# USB0_VBP2APB_WRAP_CONTROLLER_VBP_CORE_ADDR_MAP register map
Vendor: Texas Instruments
Registers are 32-bit, access per field, reset 0x0 unless marked. A register's access mark holds for its fields unless they carry their own. Offsets are as the file gives them; [hi:lo] are bit positions.

## USB0_VBP2APB_WRAP_CONTROLLER_VBP_CORE_ADDR_MAP (part 7 of 9)
0x181E8 VBP2APB_WRAP__CONTROLLER_VBP__CORE_ADDR_MAP_XECP_HOST_CTRL_LTM_REG2 reset 0x400 — HOST_CTRL_LTM_REG2. This is a vendor defined capability. This register is reserved. This register should not be accessed by software. It is described only for informative purposes.
  [11:0] DEFAULT_PCIE_LTM rw — DEFAULT_PCIE_LTM converted from ns with convert_ns2belt
0x18200 VBP2APB_WRAP__CONTROLLER_VBP__CORE_ADDR_MAP_XECP_AUX_SCRATCHPAD_0 rw — For internal use. This register may be read from or written to at any time, including whilst the CNR field in the USBSTS register is high. This is a vendor defined capability. This register is reserved. This register should not be accessed by software. It is described only for informative purposes.
0x18204 VBP2APB_WRAP__CONTROLLER_VBP__CORE_ADDR_MAP_XECP_AUX_SCRATCHPAD_1 rw — For internal use. This register may be read from or written to at any time, including whilst the CNR field in the USBSTS register is high. This is a vendor defined capability. This register is reserved. This register should not be accessed by software. It is described only for informative purposes.
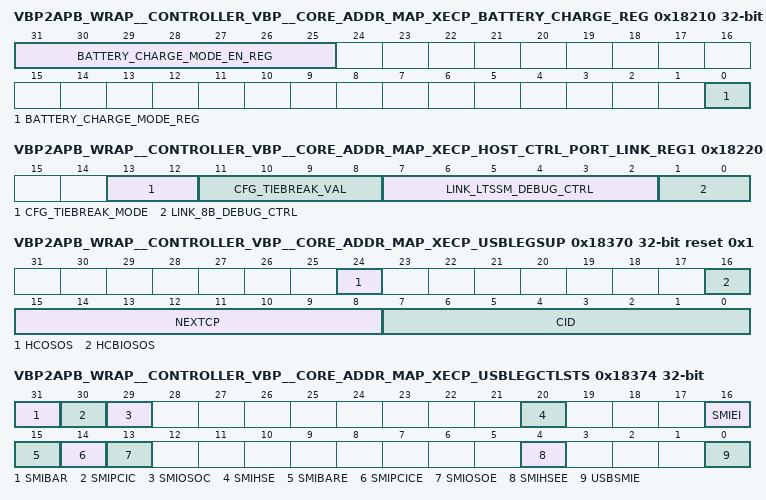
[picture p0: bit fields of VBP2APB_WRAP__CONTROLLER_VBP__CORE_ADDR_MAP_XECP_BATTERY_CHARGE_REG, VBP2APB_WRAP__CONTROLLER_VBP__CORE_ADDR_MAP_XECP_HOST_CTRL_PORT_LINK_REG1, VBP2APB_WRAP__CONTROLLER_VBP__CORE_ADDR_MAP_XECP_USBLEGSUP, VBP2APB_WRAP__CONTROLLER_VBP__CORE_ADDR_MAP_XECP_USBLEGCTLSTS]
0x18210 VBP2APB_WRAP__CONTROLLER_VBP__CORE_ADDR_MAP_XECP_BATTERY_CHARGE_REG access not given — Battery charge mode and enable register. This register may be read from or written to at any time, including whilst the CNR field in the USBSTS register is high. This is a vendor defined capability. This register is reserved. This register should not be accessed by software. It is described only for informative purposes.
  [31:25] BATTERY_CHARGE_MODE_EN_REG rw — The register allows enabling battery charge mode for each USB2 port.
  [0] BATTERY_CHARGE_MODE_REG rw — The register allows setting battery charge mode for each USB2 port.
0x18214 VBP2APB_WRAP__CONTROLLER_VBP__CORE_ADDR_MAP_XECP_BATTERY_CHARGE_REG1 reset 0x13641F4 — Battery charge control register 1. This register may be read from or written to at any time, including whilst the CNR field in the USBSTS register is high. This is a vendor defined capability. This register is reserved. This register should not be accessed by software. It is described only for informative purposes.
  [30:0] BATTERY_CHARGE_CTRL_REG1_DEFAULT rw
0x18218 VBP2APB_WRAP__CONTROLLER_VBP__CORE_ADDR_MAP_XECP_BATTERY_CHARGE_REG2 reset 0x1F4014 — Battery charge control register 2. This register may be read from or written to at any time, including whilst the CNR field in the USBSTS register is high. This is a vendor defined capability. This register is reserved. This register should not be accessed by software. It is described only for informative purposes.
  [23:0] BATTERY_CHARGE_CTRL_REG2_DEFAULT rw
0x1821C VBP2APB_WRAP__CONTROLLER_VBP__CORE_ADDR_MAP_XECP_BATTERY_CHARGE_REG3 ro — Battery charge debug register. This register may be read from or written to at any time, including whilst the CNR field in the USBSTS register is high. This is a vendor defined capability. This register is reserved. This register should not be accessed by software. It is described only for informative purposes.
  [23:0] BATTERY_CHARGE_DEBUG
0x18220 VBP2APB_WRAP__CONTROLLER_VBP__CORE_ADDR_MAP_XECP_HOST_CTRL_PORT_LINK_REG1 rw — Feature #581. This is a vendor defined capability. This register is reserved. This register should not be accessed by software. It is described only for informative purposes.
  [13:12] CFG_TIEBREAK_MODE
  [11:8] CFG_TIEBREAK_VAL
  [7:2] LINK_LTSSM_DEBUG_CTRL — link_debug_ctrl register:.link_ltssm_debug_ctrl. Possible values: stay_in_idle : bit 0 set. stay_in_ts1 : bit 1 set. stay_in_ts2 : bit 2 set. stay_in_tseq : bit 3 set. stay_in_lfps : bit 4 set. timeout_jumpover_en : bit 5 set.
  [1:0] LINK_8B_DEBUG_CTRL — link_debug_ctrl register:.link_8b_debug_ctrl. bit[0]: xmt_d102, bit[1]: xmt_comma.
0x18370 VBP2APB_WRAP__CONTROLLER_VBP__CORE_ADDR_MAP_XECP_USBLEGSUP reset 0x1 — USB Legacy Support Capability. This register is an xHCI extended capability register. This register is used by pre-OS software (BIOS) and the operating system to coordinate ownership of the xHC. This extended capability requires one additional 32-bit register for control/status information (USBLEGCTLSTS). This register is in the Aux Power well. This register may be read from or written to at any time, including whilst the CNR field in the USBSTS register is high.
  [24] HCOSOS rw — HC OS Owned Semaphore, RW. Default = '0'. System software sets this bit to request ownership of the xHC. Ownership is obtained when this bit reads as '1' and the HC BIOS Owned Semaphore bit [HCBIOSOS] reads as '0'.
  [16] HCBIOSOS rw — HC BIOS Owned Semaphore [HCBIOSOS], RW. Default = '0'. The BIOS sets this bit to establish ownership of the xHC. System BIOS will set this bit to '0' in response to a request for ownership of the xHC by system software.
  [15:8] NEXTCP ro — Next Capability Pointer, RO. This field indicates the location of the next capability with respect to the effective address of this capability. A non-zero value in this register indicates a relative offset, in Dwords, from this Dword to the beginning of the next extended capability.
  [7:0] CID ro — USB Legacy Support Capability ID, RO. This capability provides the xHCI Pre-OS to OS Handoff Synchronization support capability.
0x18374 VBP2APB_WRAP__CONTROLLER_VBP__CORE_ADDR_MAP_XECP_USBLEGCTLSTS access not given — USB Legacy Support Control Status. Pre-OS (BIOS) software uses this register to enable System Management Interrupts (SMIs) for every xHCI/USB event it needs to track. Some bits of this register are simply shadow bit of USBSTS register. This register is in the Aux Power well. This register may be read from or written to at any time, including whilst the CNR field in the USBSTS register is high.
  [31] SMIBAR — SMI on BAR, RW1C. Default = '0'. This bit is set to '1' whenever the Base Address Register [BAR] is written. (access R/W1TC)
  [30] SMIPCIC — SMI on PCI Command, RW1C. Default = '0'. This bit is set to '1' whenever the PCI Command Register is written. (access R/W1TC)
  [29] SMIOSOC — SMI on OS Ownership Change, RW1C. Default = '0'. This bit is set to '1' whenever the HC OS Owned Semaphore bit in the USBLEGSUP register transitions from '1' to a '0' or '0' to a '1'. (access R/W1TC)
  [20] SMIHSE ro — SMI on Host System Error, RO. Default = '0'. Shadow bit of Host System Error [HSE] bit in the USBSTS register. Refer to Section 5.4.2 of xHCI specification for definition and effects of the events associated with this bit being set to '1'. To clear this bit to a '0', system software shall write a '1' to the Host System Error [HSE] bit in the USBSTS register.
  [16] SMIEI ro — SMI on Event Interrupt, RO. Default = '0'. Shadow bit of Event Interrupt [EINT] bit in the USBSTS register. Refer to Section 5.4.2 of xHCI specification for definition. This bit follows the state the Event Interrupt [EINT] bit in the USBSTS register, e.g. it automatically clears when EINT clears or set when EINT is set.
  [15] SMIBARE rw — SMI on BAR Enable, RW. Default = '0'. When this bit is '1' and SMI on BAR is '1', then the host controller will issue an SMI.
  [14] SMIPCICE rw — SMI on PCI Command Enable, RW. Default = '0'. When this bit is '1' and SMI on PCI Command is '1', then the host controller will issue an SMI.
  [13] SMIOSOE rw — SMI on OS Ownership Enable, RW. Default = '0'. When this bit is a '1' AND the OS Ownership Change bit is '1', the host controller will issue an SMI.
  [4] SMIHSEE rw — SMI on Host System Error Enable, RW. Default = '0'. When this bit is a '1', and the SMI on Host System Error bit [below] in this register is a '1', the host controller will issue an SMI immediately.
  [0] USBSMIE rw — USB SMI Enable, RW. Default = '0'. When this bit is a '1', and the SMI on Event Interrupt bit [below] in this register is a '1', the host controller will issue an SMI immediately.
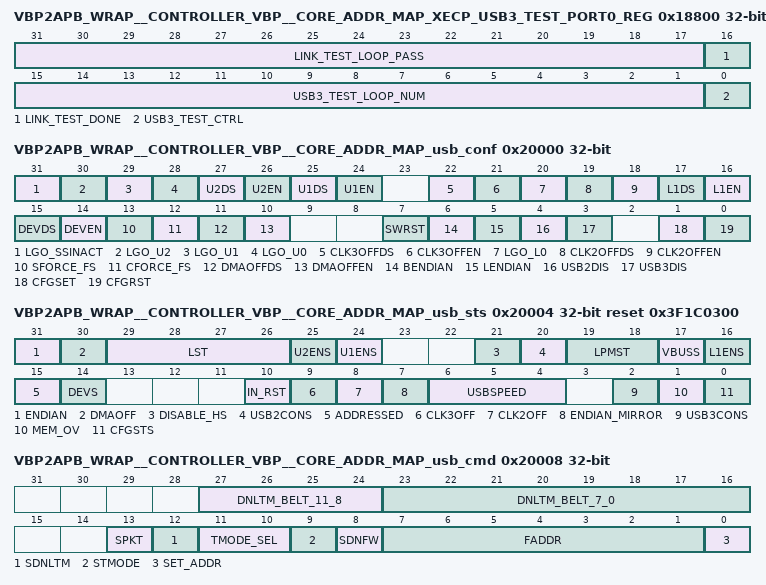
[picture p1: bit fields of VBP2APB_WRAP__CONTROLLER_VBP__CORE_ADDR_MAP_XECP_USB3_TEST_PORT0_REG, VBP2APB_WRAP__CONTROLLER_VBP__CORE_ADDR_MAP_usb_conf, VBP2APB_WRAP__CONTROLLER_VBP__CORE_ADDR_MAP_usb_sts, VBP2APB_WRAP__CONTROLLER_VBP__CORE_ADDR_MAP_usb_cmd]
0x18800 VBP2APB_WRAP__CONTROLLER_VBP__CORE_ADDR_MAP_XECP_USB3_TEST_PORT0_REG — USB3_TEST_PORT_REG. This is a vendor defined capability. This register is reserved. This register should not be accessed by software. It is described only for informative purposes.
  [31:17] LINK_TEST_LOOP_PASS ro
  [16] LINK_TEST_DONE ro — link_test_done This field should not be modified by software
  [15:1] USB3_TEST_LOOP_NUM rw
  [0] USB3_TEST_CTRL rw
0x20000 VBP2APB_WRAP__CONTROLLER_VBP__CORE_ADDR_MAP_usb_conf — Global Configuration Register
  [31] LGO_SSINACT rw — SS.Inactive state entry request [SS mode only]. This bit can be used only if USBSS-DEV is part of the CDNS USB OTG Controller [USB_CAP.OTG_READY bit is 1 while reading]. In other cases should not be used and returns 0 when read. Writing '1' will trigger an attempt to perform transition to SS.Inactive state. Should be used only if Link is in U0 or Recovery state. This bit will be automatically cleared to '0' after link layer finishes SS.Inactive request. Result of the request [link layer enters SS.Inactive or not] can be verified by reading LTS [link state] field in USB_STS register. Writing '0' has no effect
  [30] LGO_U2 rw — U2 state entry request [SS mode only]. Writing '1' will trigger an attempt to perform transition to U2 state. This bit will be automatically cleared to '0' after link layer finishes U2 request. Result of the request [link layer enters U2 or not] can be verified by reading LTS [link state] field in USB_STS register. Writing '1' has no effect when USB_STS.LGOU2ENS is set to '0'. Writing '0' has no effect.
  [29] LGO_U1 rw — U1 state entry request [SS mode only]. Writing '1' will trigger an attempt to perform transition to U1 state. This bit will be automatically cleared to '0' after link layer finishes U1 request. Result of the request [link layer enters U1 or not] can be verified by reading LTS [link state] field in USB_STS register. Writing '1' has no effect when USB_STS.LGOU1ENS is set to '0'. Writing '0' has no effect.
  [28] LGO_U0 rw — U0 state entry request [SS mode only]. Writing '1' will trigger an attempt to perform transition to U0 state. If the link is suspended [U3 state] and CPU set this bit to'1', link will start driving resume signaling on its upstream link to indicate remote wakeup. The Function Wake Notification should be send using USB_CMD.SDNFW bit. Writing '0' has no effect.
  [27] U2DS wo — U2 state entry disable [SS mode only]. Writing '1' to this bit disables link layer from entering U2 state. Status of this bit can be checked in the USB_STS register. When both U2EN and U2DS bits are set to '1' while writing to USB_CONF register, the device behaviour is udefined. Writing '0' has no effect. This bit is always '0' while reading.
  [26] U2EN wo — U2 state entry enable [device side, SS mode only]. Writing '1' to this bit enables link layer to enter U2 state. Status of this bit can be checked in the USB_STS register. Writing '0' has no effect. When both U2EN and U2DS bits are set to '1' while writing to USB_CONF register, the device behaviour is udefined. This bit is always '0' while reading.
  [25] U1DS wo — U1 state entry disable [SS mode only]. Writing '1' to this bit disables link layer from entering U1 state. Status of this bit can be checked in the USB_STS register. Writing '0' has no effect. When both U1EN and U1DS bits are set to '1' while writing to USB_CONF register, none of the operations associated with these bits will be performed. This bit is always '0' while reading.
  [24] U1EN wo — U1 state entry enable [device side, SS mode only], Writing '1' to this bit enables link layer to enter U1 state. Status of this bit can be checked in the USB_STS register. Writing '0' has no effect. When both U1EN and U1DS bits are set to '1' while writing to USB_CONF register, none of the operations associated with these bits will be performed. This bit is always '0' while reading.
  [22] CLK3OFFDS wo — USB 3.0 clock gate enable. Writing '1' to this bit disables pclk clock turning-off when device enters U3 link state in SS mode. The actual 'USB 3.0 clock gate' status in can be checked in the USB_STS.USB3OFF register. When both CLK3OFFDS and CLK3OFFEN bits are set to '1' while writing to USB_CONF register, the device behaviour is udefined. This bit is always '0' while reading.
  [21] CLK3OFFEN wo — USB 3.0 clock gate disable. Writing '1' to this bit enables pclk clock turning-off when device enters U3 link state in SS mode. The actual 'USB 3.0 clock gate' status in can be checked in the USB_STS.USB3OFF register. When both CLK3OFFDS and CLK3OFFEN bits are set to '1' while writing to USB_CONF register, the device behaviour is udefined. This bit is always '0' while reading.
  [20] LGO_L0 rw — L0 LPM state entry request [HS/FS mode only]. Writing '1' will trigger an attempt to perform transition to L0 LPM state. This bit will be automatically cleared to '0' after LPM enter L0 state. Result of the request [LPM enters L0 or not] can be verified by reading LPMST [LPM state] field in USB_STS register. Writing '0' has no effect. If the LPM is suspended [L2 state] and CPU set this bit to'1', upstream will start driving resume signaling to indicate remote wakeup.
  [19] CLK2OFFDS wo — USB 2.0 clock gate enable. Writing '1' to this bit disables hsfs clock turning-off when device enters L2 LPM state in HS/FS mode. The actual 'USB 2.0 clock gate' status in can be checked in the USB_STS.USB2OFF register. When both CLK2OFFDS and CLK2OFFEN bits are set to '1' while writing to USB_CONF register, the device behaviour is udefined. This bit is always '0' while reading.
  [18] CLK2OFFEN wo — USB 2.0 clock gate disable. Writing '1' to this bit enables hsfs clock turning-off when device enters L2 LPM state in HS/FS mode. The actual 'USB 2.0 clock gate' status in can be checked in the USB_STS.USB2OFF register. When both CLK2OFFDS and CLK2OFFEN bits are set to '1' while writing to USB_CONF register, the device behaviour is udefined. This bit is always '0' while reading.
  [17] L1DS wo — L1 LPM state entry disable [HS/FS mode only]. Writing '1' to this bit disables USB2.0 LPM from entering L1 state. Status of this bit can be checked in the USB_STS register. Writing '0' has no effect. When both L1EN and L1DS bits are set to '1' while writing to USB_CONF register, the device behaviour is udefined. This bit is always '0' while reading.
  [16] L1EN wo — L1 LPM state entry enable [device side, HS/FS mode only]. Writing '1' to this bit enables USB2.0 LPM to enter L1 state. Status of this bit can be checked in the USB_STS register. Writing '0' has no effect. When both L1EN and L1DS bits are set to '1' while writing to USB_CONF register, the device behaviour is udefined. This bit is always '0' while reading.
  [15] DEVDS wo — Device disable. Writing '1' to the DEVDS bit sets to '0' the USB_STS.DEVS bit. Check also the DEVEN bit description. Writing '0' has no effect. This bit is always '0' while reading.
  [14] DEVEN wo — Device enable. After Power-On-Reset the USBSS_DEV is disconnected from the USB bus. To connect the device into the USB bus the software has to write '1' to DEVEN bit - this couse connection of the VBUS input to the internal device logic and connetion to the USB bus as a result [inside of USBSS_DEV an internal VBUS is used which which is the and gate: VBUS input AND USB_STS.DEVS bit in SFRs]. Writing '1' to the DEVEN bit sets to '1' the USB_STS.DEVS bit. Writing '0' has no effect. This bit is always '0' while reading.
  [13] SFORCE_FS wo — Set Force Full Speed. Writing '1' to this bit forces Full Speed when USBSS-DEV operates in USB2.0 mode [disables High Speed]. When both SFORCE_FS and CFORCE_FS bits are set to '1' while writing to USB_CONF register, the device behaviour is udefined. The status of this settings can be check in the USB_STS.DISABLE_HS bit. This bit is always '0' while reading.
  [12] CFORCE_FS wo — Clear Force Full Speed. Writing '1' to this bit stop forcing Full Speed when USBSS-DEV operates in USB2.0 mode [stop disabling High Speed]. When both SFORCE_FS and CFORCE_FS bits are set to '1' while writing to USB_CONF register, the device behaviour is udefined. The status of this settings can be check in the USB_STS.DISABLE_HS bit. This bit is always '0' while reading.
  [11] DMAOFFDS wo — DMA clock turn-off disable. Writing '1' to this bit disables DMA clock turning-off when device exits U0 link state in SuperSpeed mode. When both DMAOFFDS and DMAOFFEN bits are set to '1' while writing to USB_CONF register, the device behaviour is udefined. This bit is always '0' while reading.
  [10] DMAOFFEN wo — DMA clock turn-off enable. Writing '1' to this bit enables DMA clock turning-off when device exits U0 link state in SuperSpeed mode. When both DMAOFFDS and DMAOFFEN bits are set to '1' while writing to USB_CONF register, the device behaviour is udefined. This bit is always '0' while reading.
  [7] SWRST rw — Device software reset. When set to 1, the entire USBSS-DEV is reset. The SWRST resets most flip-flops in entire USBSS-DEV. This bit is also used to connect disconnected device. Writing '0' has no effect.
  [6] BENDIAN wo — Big Endian Access. Writing '1' to this bit sets Big Endian byte order for SFRs access. Writing '0' has no effect. When both LENDIAN and BENDIAN bits are set to '1' while writing to USB_CONF register, the device behaviour is udefined. This bit is always '0' while reading.
  [5] LENDIAN wo — Little Endian access. Writing '1' to this bit sets Little Endian byte order for SFRs access. By default [after hardware reset], USBSS-DEV acts as little-endian device. Writing '0' has no effect. When both LENDIAN and BENDIAN bits are set to '1' while writing to USB_CONF register, the device behaviour is udefined. This bit is always '0' while reading.
  [4] USB2DIS wo — Disconnect USB device in HS/FS. Writing '1' to this bit disconnects USB in HS/FS. The actual USB connection status in HS/FS can be checked in the USB_STS register. Writing '0' has no effect. To connect disconnected device, CPU performs software reset [UCB_CFG.SWRST]. This bit is always '0' while reading.
  [3] USB3DIS wo — Disconnect USB device in SuperSpeed. Writing '1' to this bit disconnects USB in Super Speed. The actual USB connection status in the SS mode can be checked in the USB_STS register. If link is in U3 [SuperSpeed PHY clock is disabled] while software writes USB3DIS bit, first the hardware automatically wakes up the PHY to the P2 to turn on the PHY clock [clklink], and second, all operations related to device disconnection cease. Writing '0' has no effect. To connect disconnected device, CPU performs software reset [UCB_CFG.SWRST]. This bit is always '0' while reading.
  [1] CFGSET wo — Set Configuration. Software writes '1' to this bit when it receives SET_CONFIGURATION request with non-zero configuration number. CPU sets this bit after setting requested configuration and before setting REQ_CMPL bit in the EP_CMD register. Configuration will be set internally in the hardware when REQ_CMPL bit will be set. Writing '0' has no effect. The actual configuration status can be checked in the USB_STS register. This bit is always '0' while reading.
  [0] CFGRST wo — Reset USB device configuration. Writing '1' to this bit resets USB device configuration, leaving only EP0 IN/OUT active [all other EP-related registers will be loaded with default values]. Any configuration/interface change, including adding new IF, must be preceded with configuration reset, adding current IF's as well as new IF. Writing '0' has no effect. This bit is always '0' while reading.
0x20004 VBP2APB_WRAP__CONTROLLER_VBP__CORE_ADDR_MAP_usb_sts ro reset 0x3F1C0300 — Global Status Register
  [31] ENDIAN — SFR Endian status. Little/Big Endian byte order for SFR access: 0 - Little Endian order [default after hardware reset] 1 - Big Endian order
  [30] DMAOFF — DMA clock turn-off status. DMA clock turn-off/enable status: 0 - DMA clock is always on [default after hardware reset] 1 - DMA clock turn-off in U1, U2 and U3 [SS mode] is enabled.
  [29:26] LST — SuperSpeed Link LTSSM state. This field reflects USBSS-DEV current SuperSpeed link state: 0 - U0 State 1 - U1 State 2 - U2 State 3 - U3 State [Device Suspended] 4 - Disabled State 5 - RxDetect State 6 - Inactive State 7 - Polling State 8 - Recovery State 9 - Hot Reset State 10 - Compliance Mode State 11 - Loopback State 12:14 - Reserved 15 - Uninitialized
  [25] U2ENS — U2 state enable status [valid in SS mode only]: 0 - Entering to U2 state disabled 1 - Entering to U2 state enabled
  [24] U1ENS — U1 state enable status [valid in SS mode only]: 0 - Entering to U1 state disabled 1 - Entering to U1 state enabled
  [21] DISABLE_HS — DisableHS status [valid for HS/FS mode only] 0 - High Speed operations in USB2.0 [FS/HS] mode not disabled 1 - High Speed operations in USB2.0 [FS/HS] mode disabled
  [20] USB2CONS — HS/FS mode connection enable status [valid for HS/FS mode only]. 0 - the disconnect bit for HS/FS mode is set [USB_CONF.USB2DIS] 1 - the disconnect bit for HS/FS mode is not set [device can be connected in this mode] The actual connection status can be checked in the USB_STS.USBSPEED register
  [19:18] LPMST — HS/FS LPM state [valid for HS/FS mode only]. This field reflects USBSS-DEV current LPM [used in HS/FS mode] state: 0 - L0 State 1 - L1 State 2 - L2 State 3 - L3 State
  [17] VBUSS — Internal VBUS connection status. 0 - internal VBUS is not detected 1 - internal VBUS is detected
  [16] L1ENS — L1 LPM state enable status [valid for HS/FS mode only]. 0 - Entering to L1 LPM state disabled 1 - Entering to L1 LPM state enabled
  [15] ADDRESSED — Address status: 0 - USB device is default state 1 - USB device is at least in address state [Function Address was set by the SW]
  [14] DEVS — Device enable Status 0 - USB device is disabled [VBUS input is disconnected from internal logic] 1 - USB device is enabled [VBUS input is connected to the internal logic] This bit can be changed by setting DEVEN or DEVDS bits in USB_CONF register.
  [10] IN_RST — Controler in reset state. This bit indicate that whole [in case of POR] or part of controller [in case of SWRST or USB resets] currently is in reset state. As controller has registers in both clock domains [system, and USB], internal reset synchronization between these domains may take longer than the cause of the reset [e.g active reset_n input]. Thus it is recommended to check if controller is not in reset state, before software starts its operations [especially after POR]. 0 - Internal reset is active 1 - Internal reset is not active and controller is fully operational.
  [9] CLK3OFF — PCLK clock turn-off status. When CLK3OFF bit is '0', the phypowerdown output signal is not set to '11' in U3 link state, thus USB3.0 PHY does not turn off the pclk clock. 0 - pclk clock is always on 1 - pclk clock turn-off in U3 [SS mode] is enabled [default after hardware reset]
  [8] CLK2OFF — HS/FS clock turn-off status. When CLK2OFF bit is '0', the utmisuspendm output signal is not set low in USB2.0 suspend state [L2 state], thus USB2.0 PHY does not turn off the hsfs clock 0 - hsfs clock is always on 1 - hsfs clock turn-off in L2 [HS/FS mode] is enabled [default after hardware reset]
  [7] ENDIAN_MIRROR — Little/Big Endian byte order for SFR access. 0 - Little Endian order [default after hardware reset] 1 - Big Endian order Endian byte order for SFR access can be changed by setting BENDIAN or LEDNIAN bits in USB_CONF register.
  [6:4] USBSPEED — Device speed: 0: undef., 1: LowSpeed [not supported], 2: FullSpeed, 3: HighSpeed, 4: SuperSpeed, 5-7: Reserved
  [2] USB3CONS — SuperSpeed connection status. 0 - USB in SuperSpeed mode disconnected 1 - USB in SuperSpeed mode connected
  [1] MEM_OV — On-chip memory overflow. 0 - On-chip memory status OK 1 - On-chip memory overflow Memory overflow may occur if, during enumeration [SET_CONFIGURATION request] device software will try to turn on too many endpoints or will try to set too much endpoinds buffers [see EP_CFG.BUFFERING]. After each completion of enumeration software should check this bit, and when a memory overflow occurred, software must delete current configuration [using USB_CONF.CFGRST bit] and then set the one that requires less on-chip memory. For available memory calculation, the CDNS_USBSSDEV_ATTACHED_MEM_SIZE define parameter is used.
  [0] CFGSTS — Configuration status. 1 - device is in the configured state 0 - device is not configured This bit set during SET_CONFIGURATION request means that status stage of this request was finished successfully, thus device configuration was finished successfully.
0x20008 VBP2APB_WRAP__CONTROLLER_VBP__CORE_ADDR_MAP_usb_cmd — Global Command Register
  [27:24] DNLTM_BELT_11_8 wo — Device Notification 'Latency Tolerance Message' - BELT value [11:8] [SS mode only]. If user writes '1' to SDNLTM bit, the device will send Device Notification 'Latency Tolerance Message' with 'BELT[11:8]' field value equal to DNLTM_BELT_11_8. This field must be filled up before the USB_CMD.SDNLTM bit is set, and cannot be changed while USB_CMD.SDNLTM bit is not zero [Device Notification is being sent by the device controller] This field is always '0' while reading.
  [23:16] DNLTM_BELT_7_0 wo — Device Notification 'Latency Tolerance Message' - BELT value [7:0] / Device Notification 'Function Wake' - Interface value [SS mode only]. This field must be filled up before one of the USB_CMD.SDNLTM/SDNFW bits is set, and cannot be changed while USB_CMD.SDNLTM/SDNFW bits are not zero [Device Notification is being sent by the device controller]. If user writes '1' to SDNFW bit the device will send Device Notification 'Function Wake' with 'Interface[7:0]' field value equal to DNLTM_BELT_7_0. If user writes '1' to SDNLTM bit, the device will send Device Notification 'Latency Tolerance Message' with 'BELT[7:0]' field value equal to DNLTM_BELT_7_0. This field is always '0' while reading.
  [13] SPKT rw — Send Custom Transaction Packet [SS mode only] Writing '1' will trigger an attempt to send Custom TP as defined in the USB3.0 specification. The packet contents that will be send as TP to the host must be previously prepared in the CPKT1 [will be sent as DWORD 0 in the TP], CPKT2 [will be sent as DWORD 1 in the TP] and CPKT3 [will be sent as DWORD 2 in the TP] registers. Note that TP DWORD 3 will be automatically inserted by the device controller. This bit will be automatically cleared if this TP is sent and only then the new Custom TP [by means of SPKT bit] or other Notification TP [by means of SDNLTM or SDNFW bits] can be send again. Writing 0 has no effect. This bit cannot be written by 1 simultaneously with SDNLTM and SDNFW bits.
  [12] SDNLTM rw — Send Latency Tolerance Message Device Notification TP [SS mode only]. Writing '1' will trigger an attempt to send Device Notification 'Latency Tolerance Message' with 'BELT' field set to DNLTM_BELT. This bit will be automatically cleared if the LTM Notification TP is sent and only then the new LTM Notification TP or the other TP [by means of SPKT or SDNFW bits] can be send again. Writing '0' has no effect. This bit cannot be written by '1' simultaneously with SPKT and SDNFW bits.
  [11:10] TMODE_SEL wo — Test mode selector [HS/FS mode only]. This field contains selected Test Mode - Device will enter this Test mode when '1' is written to STMODE. USB 2.0 Test mode selector: 00 - Test_J, 01 - Test_K, 10 - Test_SE0_NAK, 11 - Test_Packet This field is always '0' while reading.
  [9] STMODE wo — Set Test Mode [HS/FS mode only]. Writing the value '1 'to this bit causes the device enters into test mode selected by the TMODE_SEL field. Writing '0' has no effect. This bit is always '0' while reading.
  [8] SDNFW rw — Send Function Wake Device Notification TP [SS mode only]. Writing '1' will trigger an attempt to send 'Device Notification' with 'Interface' field set to DNFW_INT. This bit will be automatically cleared if the FW Notification TP is sent and only then the new FW Notification TP or the other TP [by means of SPKT or SDNLTM bits] can be send again. Writing '0' has no effect. This bit cannot be written by '1' simultaneously with SPKT and SDNLTM bits.
  [7:1] FADDR wo — Function Address. This field is saved to the device only when the field SET_ADDR is set '1 ' during write to USB_CMD register. Software is responsible for entering the address of the device during SET_ADDRESS request service. This field should be set immediately after the SETUP packet is decoded, and prior to confirmation of the status phase [what is done by bit EP_CMD.REQ_CMPL] Verify that the device successfully completed the SET_ADDRESS request and is in ADRESSED state [as defined in USB3 spec] can be realized by checking the bit USB_STS. ADRESSED. USB_CMD.FADDR field can also be read at any time. This field is always '0' while reading.
  [0] SET_ADDR wo — Set Function Address. Writing the value '1 'to this bit causes the device is assigned to the USB Function Address according to the FADDR field. The device address must be saved by software when operating SET_ADDRESS request. After saving device address, software should set the EP_CMD.ERDY bit [as with all other requests] to quit the setup phase and then set bit EP_CMD.REQ_CMPL to confirm the status of the host phase. Writing '0 'has no effect. This bit is always '0' while reading.
0x2000C VBP2APB_WRAP__CONTROLLER_VBP__CORE_ADDR_MAP_usb_iptn ro — USB ITPN Reserved
  [13:0] ITPN — ITP[SS] / SOF [HS/FS] number. In SS mode this field represent number of last ITP received from host. In HS/FS mode this field represent number of last SOF received from host.
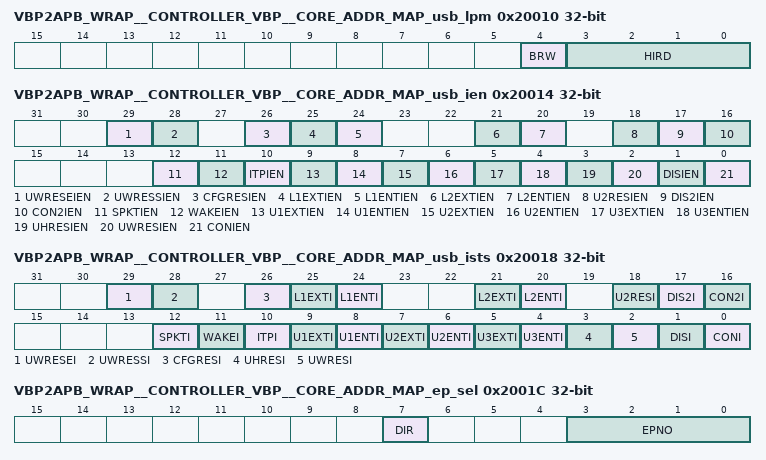
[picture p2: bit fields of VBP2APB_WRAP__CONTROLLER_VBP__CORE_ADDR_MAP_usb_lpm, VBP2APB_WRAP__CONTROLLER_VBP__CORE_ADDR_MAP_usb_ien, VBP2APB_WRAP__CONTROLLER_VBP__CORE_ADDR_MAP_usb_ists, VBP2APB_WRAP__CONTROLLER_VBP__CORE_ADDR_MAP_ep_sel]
0x20010 VBP2APB_WRAP__CONTROLLER_VBP__CORE_ADDR_MAP_usb_lpm ro — USB LPM Register
  [4] BRW — Remote Wakeup Enable [bRemoteWake]
  [3:0] HIRD — Host Initiated Resume Duration. This is the Resume duration from L1 LPM state, received from the host in the latest Extended Token packet. For more information see chapter: 'HS/FS mode - Link Power Management'
0x20014 VBP2APB_WRAP__CONTROLLER_VBP__CORE_ADDR_MAP_usb_ien — Interrupt Enable Register
  [29] UWRESEIEN rw — End of the USB SS warm reset interrupt enable. This bit enables requesting a UWRESEI interrupt
  [28] UWRESSIEN rw — Start of the USB SS warm reset interrupt enable. This bit enables requesting a UWRESSI interrupt
  [26] CFGRESIEN rw — Configuration reset interrupt enable. This bit enables requesting a CFGRESI interrupt
  [25] L1EXTIEN rw — LPM L1 state exit interrupt enable. This bit enables requesting an L1EXTI interrupt.
  [24] L1ENTIEN rw — LPM L1 state enter interrupt enable. This bit enables requesting an L1ENTI interrupt.
  [21] L2EXTIEN rw — LPM L2 state exit interrupt enable. This bit enables requesting a L2EXTI interrupt.
  [20] L2ENTIEN rw — LPM L2 state enter interrupt enable. This bit enables requesting a L2ENTI interrupt.
  [18] U2RESIEN rw — USB reset [HS/FS mode] interrupt enable. This bit enables requesting an U2RESI interrupt.
  [17] DIS2IEN rw — HS/FS mode disconnection interrupt enable. This bit enables requesting a DIS2I interrupt.
  [16] CON2IEN rw — HS/FS mode connection interrupt enable. This bit enables requesting a CON2I interrupt.
  [12] SPKTIEN rw — Send Custom Packet interrupt enable. This bit enables requesting a Send Custom Packet interrupt.
  [11] WAKEIEN rw — Wakeup interrupt enable. This bit enables requesting a Wakeup interrupt.
  [10] ITPIEN rw — ITP/SOF packet detected interrupt enable. This bit enables requesting an ITPI interrupt.
  [9] U1EXTIEN rw — SS link U1 state exit interrupt enable. This bit enables requesting an U1EXTI interrupt.
  [8] U1ENTIEN rw — SS link U1 state enter interrupt enable. This bit enables requesting an U1ENTI interrupt.
  [7] U2EXTIEN rw — SS link U2 state exit interrupt enable. This bit enables requesting an U2EXTI interrupt.
  [6] U2ENTIEN rw — SS link U2 state enter interrupt enable. This bit enables requesting an U2ENTI interrupt.
  [5] U3EXTIEN rw — SS link U3 state exit interrupt enable [wakeup]. This bit enables requesting an U3EXTI interrupt.
  [4] U3ENTIEN rw — SS link U3 state enter interrupt enable [suspend]. This bit enables requesting an U3ENTI interrupt.
  [3] UHRESIEN rw — USB SS hot reset interrupt enable. This bit enables requesting an UHRESI interrupt.
  [2] UWRESIEN rw — USB SS warm reset interrupt enable. This bit enables requesting an UWRESI interrupt.
  [1] DISIEN rw — SS disconnection interrupt enable. This bit enables requesting a DISI interrupt.
  [0] CONIEN rw — SS connection interrupt enable. This bit enables requesting a CONI interrupt.
0x20018 VBP2APB_WRAP__CONTROLLER_VBP__CORE_ADDR_MAP_usb_ists access not given — USB Interrupt Status Register Each bit (interrupt flag) from this register can be cleared by writing '1'.
  [29] UWRESEI — End of the USB warm reset detected. This interrupt is requested after the SuperSpeed warm reset ends. This interrupt is reported on the irqs[0] pin. (access R/W1TC)
  [28] UWRESSI — Start of the USB warm reset detected. This interrupt is requested as soon as the SuperSpeed warm reset signalling is detected. This interrupt is reported on the irqs[0] pin. (access R/W1TC)
  [26] CFGRESI — USB configuration reset detected. This interrupt is requested after the device internally resets its endpoints onfiguration. This is done after each USB reset [UWRESI, UWRESI or U2RESI], after each connection event [CONI, CON2I] and after configuration reset initiated by software [USB_CONF.CFGRST]. Generally this interrupt is generated in the same time as mentioned interrupts, however due to internal clock domain synchronisation this configuration reset can be performed a little later, so one can use this interrupt to perform some software operations. This interrupt informs that controller did the following operations: disabled all non control endpoints, cleared all pending endpoints transfers and interrupts. The configuration reset does not clear general device configuration [set in USB_CONF] and EP0 configuration settings. This interrupt is reported on the irqs[0] pin. (access R/W1TC)
  [25] L1EXTI — LPM L1 state exit detected This interrupt informs that HS/FS LPM exit L1 state. This interrupt is reported on the irqs[0] pin. (access R/W1TC)
  [24] L1ENTI — LPM L1 state enter detected This interrupt informs that HS/FS LPM enter L1 state. This interrupt is reported on the irqs[0] pin. (access R/W1TC)
  [21] L2EXTI — LPM L2 state exit detected This interrupt informs that HS/FS LPM exit L2 state. This interrupt is reported on the irqs[1] pin. (access R/W1TC)
  [20] L2ENTI — LPM L2 state enter detected This interrupt informs that HS/FS LPM enter L2 state. This interrupt is reported on the irqs[0] pin. (access R/W1TC)
  [18] U2RESI — USB reset [HS/FS mode] detected This interrupt is requested after the USB reset in HS/FS mode ends. This interrupt is reported on the irqs[0] pin. (access R/W1TC)
  [17] DIS2I — HS/FS mode disconnection detected This interrupt informs that HS/FS upstream port was disconncted from the USB line. This interrupt is reported on the irqs[0] pin. (access R/W1TC)
  [16] CON2I — HS/FS mode connection detected This interrupt informs that HS/FS upstream port was conncted to the USB line This interrupt is reported on the irqs[0] pin. (access R/W1TC)
  [12] SPKTI — Send Custom Packet This interrupt informs that Custom Packet prepared in the USB_CPKT1-3 registers and triggered with USB_CMD.SPKT bit was already sent. This interrupt is reported on the irqs[0] pin. (access R/W1TC)
  [11] WAKEI — This interrupt informs that at wakeup pin appeared active state. This interrupt is reported on the irqs[1] pin. (access R/W1TC)
  [10] ITPI — ITP/SOF packet detected In SuperSpeed mode this interrupt informs that ITP packet was received. In FS/HS mode this interrupt informs that SOF was detected. This interrupt is reported on the irqs[0] pin. (access R/W1TC)
  [9] U1EXTI — SS link U1 state exit detected This interrupt informs that SuperSpeed link exit U1 state. This interrupt is reported on the irqs[0] pin. (access R/W1TC)
  [8] U1ENTI — SS link U1 state enter detected This interrupt informs that SuperSpeed link enter U1 state. This interrupt is reported on the irqs[0] pin. (access R/W1TC)
  [7] U2EXTI — SS link U2 state exit detected This interrupt informs that SuperSpeed link exit U2 state. This interrupt is reported on the irqs[0] pin. (access R/W1TC)
  [6] U2ENTI — SS link U2 state enter detected This interrupt informs that SuperSpeed link enter U2 state. This interrupt is reported on the irqs[0] pin. (access R/W1TC)
  [5] U3EXTI — SS link U3 state exit detected [wakeup] This interrupt informs that SuperSpeed link exit U3 state. This interrupt is reported on the irqs[1] pin. (access R/W1TC)
  [4] U3ENTI — SS link U3 state enter detected [suspend] This interrupt informs that SuperSpeed link enter U3 state. This interrupt is reported on the irqs[0] pin. (access R/W1TC)
  [3] UHRESI — USB SS hot reset detected This interrupt is requested after the SuperSpeed hot reset ends. This interrupt is reported on the irqs[0] pin. (access R/W1TC)
  [2] UWRESI — USB SS warm reset detected This interrupt is requested after the SuperSpeed warm reset ends or when USBSS-DEVs LTSSM exits Polling.LFPS state. After this reset, SW should reininitialize the controller. This interrupt is reported on the irqs[0] pin. (access R/W1TC)
  [1] DISI — SS disconnection detected This interrupt informs that SuperSpeed link was disconncted from the USB line. This interrupt is reported on the irqs[0] pin. (access R/W1TC)
  [0] CONI — SS connection detected This interrupt informs that SuperSpeed link was conncted to the USB line This interrupt is reported on the irqs[0] pin. (access R/W1TC)
0x2001C VBP2APB_WRAP__CONTROLLER_VBP__CORE_ADDR_MAP_ep_sel — Endpoint Select Register This register is used in conjunction with Endpoint Configuration, Command, Status, and Transfer ring address registers. If processor wants to access a specific endpoint, it has to first identify this endpoint by selecting it in Endpoint select register.
  [7] DIR rw — Selected Endpoint direction. 0-OUT Endpoint selected, 1-IN Endpoint selected
  [3:0] EPNO rw — Selected Endpoint number
0x20020 VBP2APB_WRAP__CONTROLLER_VBP__CORE_ADDR_MAP_ep_traddr rw — Endpoint Transfer Ring Address Register All bytes of the register must be written, to store the TRADDR value. If all bytes of this register are not written at the same time (e.g. byte access), the MSB must be written at the end of the operation
  [31:0] TRADDR — Transfer Ring address. Address of transfer ring for endpoint selected by endpoint select register. Based on this address, DMA will fetch transfer descriptors from system memory. This register can be used as dequeue pointer. CPU can use this register [read it or write to it] only when endpoint is configured and enabled [using EP_CFG register]
